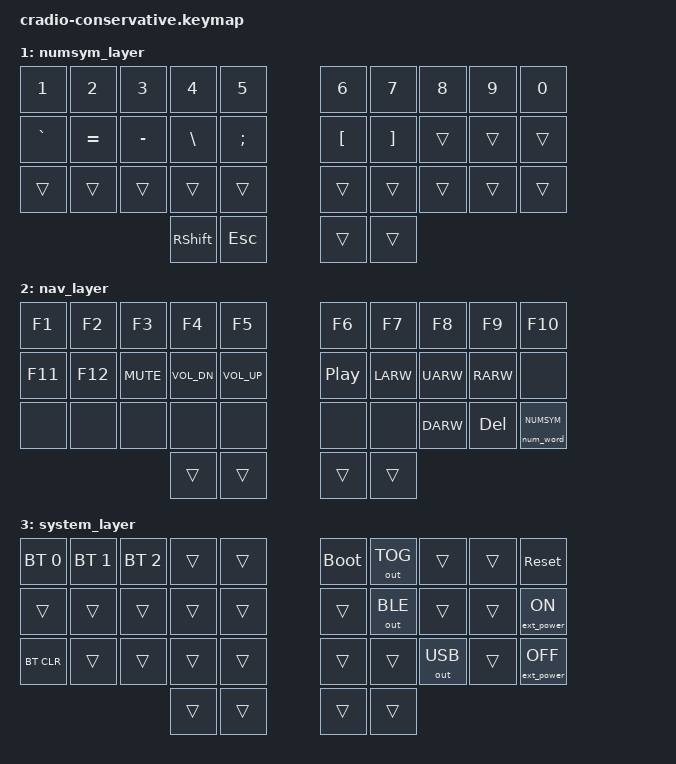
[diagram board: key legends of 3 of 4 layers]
// Copyright (c) 2022 The ZMK Contributors
// SPDX-License-Identifier: MIT
//
// OPTION 1: CONSERVATIVE ENHANCEMENT
// - Keeps your original layout intact
// - Adds panic mode (double thumb tap → base)
// - Adds sticky behavior to ENTER/BACKSPACE
// - Fine-tuned timing to reduce roll interference
// - Optional toggle layer access via combos

#include <behaviors/num_word.dtsi>
#include <behaviors.dtsi>
#include <dt-bindings/zmk/keys.h>
#include <dt-bindings/zmk/bt.h>
#include <dt-bindings/zmk/outputs.h>
#include <dt-bindings/zmk/ext_power.h>

// ---------- Layer indexes ----------
#define BASE    0 
#define NUMSYM  1
#define NAV     2
#define SYSTEM  3

// ---------- Home-row Mods via single hold-tap ----------
#define HRML(k1,k2,k3,k4) &ht LSHFT k1  &ht LALT k2   &ht LCTRL k3   &ht LGUI k4
#define HRMR(k1,k2,k3,k4) &ht RGUI k1   &ht RCTRL k2  &ht RALT k3    &ht RSHFT k4

/ {
    behaviors {
        ht: hold_tap {
            compatible = "zmk,behavior-hold-tap";
            #binding-cells = <2>;
            flavor = "tap-preferred";
            // Slightly longer to reduce roll interference
            tapping-term-ms = <220>;
            // Faster quick-tap for rapid typing
            quick-tap-ms = <100>;
            // More idle time to prevent conflicts
            require-prior-idle-ms = <125>;
            bindings = <&kp>, <&kp>;
        };

        // Sticky behavior for thumb keys
        sk_enter: sticky_enter {
            compatible = "zmk,behavior-sticky-key";
            #binding-cells = <1>;
            bindings = <&kp>;
            release-after-ms = <1000>;
            quick-release;
        };

        sk_bspc: sticky_backspace {
            compatible = "zmk,behavior-sticky-key";
            #binding-cells = <1>;
            bindings = <&kp>;
            release-after-ms = <1000>;
            quick-release;
        };
    };

    // ---------- Combos for enhanced functionality ----------
    combos {
        compatible = "zmk,combos";
        
        // Panic mode - double thumb tap returns to base from any layer
        combo_panic {
            timeout-ms = <50>;
            key-positions = <30 33>; // Both thumbs
            bindings = <&to BASE>;
            layers = <BASE NUMSYM NAV SYSTEM>;
        };

        // Optional toggle access to layers (experimental)
        combo_toggle_nav {
            timeout-ms = <40>;
            key-positions = <14 15>; // T G
            bindings = <&tog NAV>;
            layers = <BASE>;
        };

        combo_toggle_numsym {
            timeout-ms = <40>;
            key-positions = <15 16>; // G H
            bindings = <&tog NUMSYM>;
            layers = <BASE>;
        };
    };

    // ---------- Conditional tri-layer ----------
    conditional_layers {
        compatible = "zmk,conditional-layers";
        system_layer {
            if-layers = <NAV NUMSYM>;
            then-layer = <SYSTEM>;
        };
    };

    keymap {
        compatible = "zmk,keymap";
        base_layer {
            bindings = <
        //╭──────────┬──────────┬──────────┬──────────┬──────────╮   ╭──────────┬──────────┬──────────┬──────────┬──────────╮
        //│  Q       │  W       │  E       │  R       │  T       │   │  Y       │  U       │  I       │  O       │  P       │
             &kp Q      &kp W      &kp E      &kp R      &kp T          &kp Y      &kp U      &kp I      &kp O      &kp P
        //├──────────┼──────────┼──────────┼──────────┼──────────┤   ├──────────┼──────────┼──────────┼──────────┼──────────┤
        //│  A       │  S       │  D       │  F       │  G       │   │  H       │  J       │  K       │  L       │ ' "      │
             HRML(A,    S,         D,         F)         &kp G          &kp H      HRMR(J,    K,         L,        SQT)
        //├──────────┼──────────┼──────────┼──────────┼──────────┤   ├──────────┼──────────┼──────────┼──────────┼──────────┤
        //│  Z       │  X       │  C       │  V       │  B       │   │  N       │  M       │ , <      │ . >      │ / ?      │
            &kp Z      &kp X      &kp C      &kp V      &kp B          &kp N      &kp M      &kp COMMA  &kp DOT    &kp FSLH
        //╰──────────┴──────────┴──────────┼──────────┼──────────┤   ├──────────┼──────────┼──────────┴──────────┴──────────╯
                                         &lt NAV TAB   &sk_enter ENTER    &sk_bspc BSPC  &lt NUMSYM SPACE
        //                                 ╰──────────┴──────────╯   ╰──────────┴──────────╯
            >;
        };

        numsym_layer {
            bindings = <
        //╭──────────┬──────────┬──────────┬──────────┬──────────╮   ╭──────────┬──────────┬──────────┬──────────┬──────────╮
        //│ 1        │ 2        │ 3        │ 4        │ 5        │   │ 6        │ 7        │ 8        │ 9        │  0       │
            &kp N1     &kp N2     &kp N3     &kp N4     &kp N5         &kp N6     &kp N7     &kp N8     &kp N9     &kp N0
        //├──────────┼──────────┼──────────┼──────────┼──────────┤   ├──────────┼──────────┼──────────┼──────────┼──────────┤
        //│ ` ~      │ = +      │ - _     │  \ |      │  ; :     │   │ [ {      │ ] }      │          │          │          │
            &kp GRAVE   &kp EQUAL  &kp MINUS  &kp BSLH   &kp SEMI       &kp LBKT   &kp RBKT   &trans     &trans     &trans
        //├──────────┼──────────┼──────────┼──────────┼──────────┤   ├──────────┼──────────┼──────────┼──────────┼──────────┤
        //│          │          │          │          │          │   │          │          │          │          │          │
            &trans     &trans     &trans     &trans     &trans         &trans     &trans     &trans     &trans     &trans
        //╰──────────┴──────────┴──────────┼──────────┼──────────┤   ├──────────┼──────────┼──────────┴──────────┴──────────╯
                                                &kp RSHFT     &kp ESC        &trans     &trans
        //                                 ╰──────────┴──────────╯   ╰──────────┴──────────╯
            >;
        };

        nav_layer {
            bindings = <
        //╭──────────┬──────────┬──────────┬──────────┬──────────╮   ╭──────────┬──────────┬──────────┬──────────┬──────────╮
        //│  F1      │  F2      │  F3      │  F4      │ F5       │   │  F6      │  F7      │  F8      │  F9      │  F10     │
             &kp F1      &kp F2     &kp F3     &kp F4    &kp F5          &kp F6     &kp F7     &kp F8     &kp F9     &kp F10
        //├──────────┼──────────┼──────────┼──────────┼──────────┤   ├──────────┼──────────┼──────────┼──────────┼──────────┤
        //│  F11     │  F12     │  Mute    │  VOL DN  │ VOL UP   │   │          │  LEFT    │  UP      │ RIGHT    │          │
             &kp F11    &kp F12   &kp K_MUTE &kp C_VOL_DN &kp C_VOL_UP   &kp C_PP     &kp LARW   &kp UARW    &kp RARW   &none
        //├──────────┼──────────┼──────────┼──────────┼──────────┤   ├──────────┼──────────┼──────────┼──────────┼──────────┤
        //│          │          │          │          │          │   │          │          │ DOWN     │   DEL    │ NUM_WORD │
             &none     &none       &none      &none      &none          &none     &none       &kp DARW    &kp DEL  &num_word NUMSYM
        //╰──────────┴──────────┴──────────┼──────────┼──────────┤   ├──────────┼──────────┼──────────┴──────────┴──────────╯
                                                 &trans     &trans         &trans     &trans
        //                                 ╰──────────┴──────────╯   ╰──────────┴──────────╯
            >;
        };

        system_layer {
            bindings = <
        //╭──────────┬──────────┬──────────┬──────────┬──────────╮   ╭──────────┬──────────┬──────────┬──────────┬──────────╮
        //│ PROFILE 0│ PROFILE 1│PROFILE 2 │          │		 │   │BOOTLOADER│          │          │          │  RESET   │
        &bt BT_SEL 0  &bt BT_SEL 1 &bt BT_SEL 2 &trans  	&trans        &bootloader &out OUT_TOG &trans      &trans   &sys_reset
        //├──────────┼──────────┼──────────┼──────────┼──────────┤   ├──────────┼──────────┼──────────┼──────────┼──────────┤
        //│          │          │          │          │          │   │          │          │          │          │EP ON     │
           &trans      &trans     &trans     &trans    &trans          &trans &out OUT_BLE     &trans     &trans  &ext_power EP_ON
        //├──────────┼──────────┼──────────┼──────────┼──────────┤   ├──────────┼──────────┼──────────┼──────────┼──────────┤
        //│ CLEAR BT │          │          │          │	         │   │          │          │          │          │EP OFF    │
           &bt BT_CLR  &trans     &trans    &trans	&trans          &trans     &trans   &out OUT_USB  &trans  &ext_power EP_OFF
        //╰──────────┴──────────┴──────────┼──────────┼──────────┤   ├──────────┼──────────┼──────────┴──────────┴──────────╯
                                          &trans     &trans         &trans     &trans
        //                                 ╰──────────┴──────────╯   ╰──────────┴──────────╯
            >;
        };
    };
};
